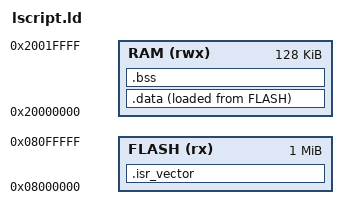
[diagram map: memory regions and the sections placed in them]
/*
 * linker script for stm32f1
 */
MEMORY
{
    FLASH (rx) : ORIGIN = 0x08000000, LENGTH = 1M
    RAM (rwx) : ORIGIN = 0x20000000, LENGTH = 128K
}

__stack_start = ORIGIN(RAM) + LENGTH(RAM);

SECTIONS
{
    .isr_vector :
    {
        KEEP(*(.isr_vector))
        KEEP(*(.text.vtable))
        *(.text*)
        *(.rodata*)
    } > FLASH

    .data :
    {
        *(.data*)
    } > RAM AT > FLASH

    .bss :
    {
        *(.bss*)
        *(COMMON)
    } > RAM
}
